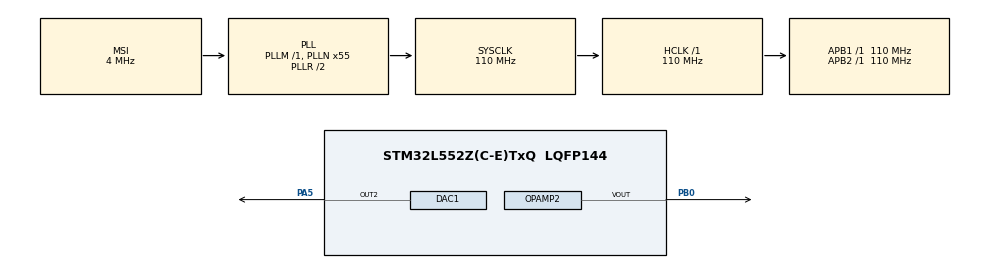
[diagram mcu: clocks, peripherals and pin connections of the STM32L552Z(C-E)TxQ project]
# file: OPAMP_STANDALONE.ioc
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DAC1.DAC_Channel-DAC_OUT2_ExtAndInt=DAC_CHANNEL_2
DAC1.DAC_Trigger-DAC_OUT2_ExtAndInt=DAC_TRIGGER_T2_TRGO
Dma.DAC1_CH2.0.Channel_PRIV_NPRIV=DMA_CHANNEL_NPRIV_DISABLE
Dma.DAC1_CH2.0.Direction=DMA_MEMORY_TO_PERIPH
Dma.DAC1_CH2.0.EventEnable=DISABLE
Dma.DAC1_CH2.0.Instance=DMA1_Channel1
Dma.DAC1_CH2.0.MemDataAlignment=DMA_MDATAALIGN_WORD
Dma.DAC1_CH2.0.MemInc=DMA_MINC_ENABLE
Dma.DAC1_CH2.0.Mode=DMA_CIRCULAR
Dma.DAC1_CH2.0.PeriphDataAlignment=DMA_PDATAALIGN_WORD
Dma.DAC1_CH2.0.PeriphInc=DMA_PINC_DISABLE
Dma.DAC1_CH2.0.Polarity=HAL_DMAMUX_REQ_GEN_RISING
Dma.DAC1_CH2.0.Priority=DMA_PRIORITY_HIGH
Dma.DAC1_CH2.0.RequestNumber=1
Dma.DAC1_CH2.0.SignalID=NONE
Dma.DAC1_CH2.0.SyncEnable=DISABLE
Dma.DAC1_CH2.0.SyncPolarity=HAL_DMAMUX_SYNC_NO_EVENT
Dma.DAC1_CH2.0.SyncRequestNumber=1
Dma.DAC1_CH2.0.SyncSignalID=NONE
Dma.Request0=DAC1_CH2
Mcu.Family=STM32L5
Mcu.Name=STM32L552Z(C-E)TxQ
Mcu.Package=LQFP144
NVIC.DAC_IRQn=true\:0\:0\:false\:false\:true\:true\:true\:true
NVIC.DMA1_Channel1_IRQn=true\:0\:0\:false\:false\:true\:false\:true\:true
NVIC.PriorityGroup=NVIC_PRIORITYGROUP_3
OPAMP2.PowerSupplyRange=OPAMP_POWERSUPPLY_HIGH
PA5.Signal=COMP_DAC12_group
PB0.Mode=Follower-DAC_OUT2-INP
PB0.Signal=OPAMP2_VOUT
ProjectManager.HeapSize=0x200
ProjectManager.StackSize=0x400
ProjectManager.TargetToolchain=EWARM V8.32
RCC.AHBFreq_Value=110000000
RCC.APB1Freq_Value=110000000
RCC.APB1TimFreq_Value=110000000
RCC.APB2Freq_Value=110000000
RCC.APB2TimFreq_Value=110000000
RCC.CortexFreq_Value=110000000
RCC.HCLKFreq_Value=110000000
RCC.HSE_VALUE=16000000
RCC.HSI48_VALUE=48000000
RCC.HSI_VALUE=16000000
RCC.LSE_VALUE=32768
RCC.MSI_VALUE=4000000
RCC.PLLN=55
RCC.SYSCLKFreq_VALUE=110000000
RCC.SYSCLKSource=RCC_SYSCLKSOURCE_PLLCLK
RCC.VCOOutputFreq_Value=220000000
SH.COMP_DAC12_group.0=DAC1_OUT2,DAC_OUT2_ExtAndInt
TIM2.Period=0xfff
TIM2.TIM_MasterOutputTrigger=TIM_TRGO_UPDATE
VP_ICACHE_VS_ICACHE.Mode=DirectMappedCache
VP_PWR_VS_DBSignals.Mode=DisableDeadBatterySignals
VP_TIM2_VS_ClockSourceINT.Mode=Internal
board=custom

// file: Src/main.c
/* USER CODE BEGIN Header */
/**
  ******************************************************************************
  * @file    OPAMP/OPAMP_STANDALONE/Src/main.c
  * @author  MCD Application Team
  * @brief   This example provides a short description of how to use the OPAMP
  *          peripheral to amplify several signals.
  ******************************************************************************
  * @attention
  *
  * Copyright (c) 2019 STMicroelectronics.
  * All rights reserved.
  *
  * This software is licensed under terms that can be found in the LICENSE file
  * in the root directory of this software component.
  * If no LICENSE file comes with this software, it is provided AS-IS.
  *
  ******************************************************************************
  */
/* USER CODE END Header */
#include "main.h"

/* USER CODE BEGIN PD */
const uint32_t Sine12bit[32] = {511, 611, 707, 796, 847, 874, 984, 1014, 1023,
                                1014, 984, 937, 874, 796, 707, 611, 511, 411,
                                315, 227, 149, 149, 38, 9, 0, 9, 38, 86, 149, 227,
                                315, 411};
/* USER CODE END PD */

DAC_HandleTypeDef hdac1;
DMA_HandleTypeDef hdma_dac1_ch2;

OPAMP_HandleTypeDef hopamp2;

TIM_HandleTypeDef htim2;

/* USER CODE BEGIN PV */
/* set to 1 after User push-button interrupt  */
__IO uint32_t UserButtonStatus = 0;
/* USER CODE END PV */

void SystemClock_Config(void);
static void MX_GPIO_Init(void);
static void MX_DMA_Init(void);
static void MX_ICACHE_Init(void);
static void MX_OPAMP2_Init(void);
static void MX_DAC1_Init(void);
static void MX_TIM2_Init(void);
/* USER CODE BEGIN PFP */
static void OPAMP_Config_Power(uint32_t powermode);
/* USER CODE END PFP */

/* USER CODE BEGIN 0 */
/**
  * @brief  Configure OPAMP.
  * @param  powermode: power mode in use
  * @retval None
  */
static void OPAMP_Config_Power(uint32_t powermode)
  {
    /* Deinit  OPAMP */
    HAL_OPAMP_DeInit(&hopamp2);

    /* Select power mode */
    if (powermode == OPAMP_POWERMODE_NORMAL)
    {
      MX_OPAMP2_Init();
    }
    else
    {
      hopamp2.Instance = OPAMP2;
      hopamp2.Init.PowerSupplyRange = OPAMP_POWERSUPPLY_HIGH;
      hopamp2.Init.Mode = OPAMP_FOLLOWER_MODE;
      hopamp2.Init.NonInvertingInput = OPAMP_NONINVERTINGINPUT_DAC_CH;
      hopamp2.Init.PowerMode = OPAMP_POWERMODE_LOWPOWER;
      hopamp2.Init.UserTrimming = OPAMP_TRIMMING_FACTORY;
      if (HAL_OPAMP_Init(&hopamp2) != HAL_OK)
      {
        Error_Handler();
      }
    }
}

/**
  * @brief  EXTI line rising detection callback.
  * @param  GPIO_Pin Specifies the port pin connected to corresponding EXTI line.
  * @retval None
  */

void HAL_GPIO_EXTI_Rising_Callback(uint16_t GPIO_Pin)
{
  static uint32_t first_transition_timing = 0;
  uint32_t current_transition_timing = 0;

  current_transition_timing = HAL_GetTick();

  /* 500 ms */
  if ((current_transition_timing - first_transition_timing) > 500)
  {
    /* Wait that user release the User push-button */
    while(BSP_PB_GetState(BUTTON_USER) == GPIO_PIN_SET)
    {
    }

    /* A genuine transition is detected */
    UserButtonStatus = 1;

    /* current transition timing becomes first transition timing */
    first_transition_timing = current_transition_timing;
  }
  else
  /* Next transitions within 500 ms window time span are ignored */
  {
  }
}
/* USER CODE END 0 */

int main(void)
{
  /* USER CODE BEGIN 1 */
  uint32_t examplestate = 0;
  /* USER CODE END 1 */

  /* MCU Configuration--------------------------------------------------------*/

  /* Reset of all peripherals, Initializes the Flash interface and the Systick. */
  HAL_Init();

  /* Configure the system clock */
  SystemClock_Config();

  /* Initialize all configured peripherals */
  MX_GPIO_Init();
  MX_DMA_Init();
  MX_ICACHE_Init();
  MX_OPAMP2_Init();
  MX_DAC1_Init();
  MX_TIM2_Init();
  /* USER CODE BEGIN 2 */

  /*##- Configure and enable the User push-button in EXTI mode used as DMA external request signal #####*/
  if (BSP_PB_Init(BUTTON_USER, BUTTON_MODE_EXTI) != BSP_ERROR_NONE)
  {
    while(1);
  }

  /* Enable TIM peripheral counter */
  HAL_TIM_Base_Start(&htim2);

  /* Start DAC with DMA used as input signal */
  if(HAL_DAC_Start_DMA(&hdac1, DAC_CHANNEL_2, (uint32_t*)Sine12bit,
                       sizeof (Sine12bit) / sizeof (uint32_t),
                       DAC_ALIGN_12B_R) != HAL_OK)
  {
    Error_Handler();
  }

  /* USER CODE END 2 */

  /* Infinite loop */
  /* USER CODE BEGIN WHILE */
  while (1)
  {

    /* Test if user an action occurred on the User push-button */
    if (UserButtonStatus == 1)
    {
      UserButtonStatus = 0;
      /* Change the mode */
      if (examplestate == 0)
      {
        /* normal mode */
        OPAMP_Config_Power(OPAMP_POWERMODE_NORMAL);
        examplestate= 1;
      }
      else /* normal mode */
      {
        /* Low power mode */
        OPAMP_Config_Power(OPAMP_POWERMODE_LOWPOWER);
        examplestate= 0;
      }

      if(HAL_OK != HAL_OPAMP_Start(&hopamp2))
      {
        Error_Handler();
      }
    }

    /* USER CODE END WHILE */

  }
}

void SystemClock_Config(void)
{
  RCC_OscInitTypeDef RCC_OscInitStruct = {0};
  RCC_ClkInitTypeDef RCC_ClkInitStruct = {0};

  /** Configure the main internal regulator output voltage
  */
  if (HAL_PWREx_ControlVoltageScaling(PWR_REGULATOR_VOLTAGE_SCALE0) != HAL_OK)
  {
    Error_Handler();
  }

  /** Initializes the RCC Oscillators according to the specified parameters
  * in the RCC_OscInitTypeDef structure.
  */
  RCC_OscInitStruct.OscillatorType = RCC_OSCILLATORTYPE_MSI;
  RCC_OscInitStruct.MSIState = RCC_MSI_ON;
  RCC_OscInitStruct.MSICalibrationValue = RCC_MSICALIBRATION_DEFAULT;
  RCC_OscInitStruct.MSIClockRange = RCC_MSIRANGE_6;
  RCC_OscInitStruct.PLL.PLLState = RCC_PLL_ON;
  RCC_OscInitStruct.PLL.PLLSource = RCC_PLLSOURCE_MSI;
  RCC_OscInitStruct.PLL.PLLM = 1;
  RCC_OscInitStruct.PLL.PLLN = 55;
  RCC_OscInitStruct.PLL.PLLP = RCC_PLLP_DIV7;
  RCC_OscInitStruct.PLL.PLLQ = RCC_PLLQ_DIV2;
  RCC_OscInitStruct.PLL.PLLR = RCC_PLLR_DIV2;
  if (HAL_RCC_OscConfig(&RCC_OscInitStruct) != HAL_OK)
  {
    Error_Handler();
  }

  /** Initializes the CPU, AHB and APB buses clocks
  */
  RCC_ClkInitStruct.ClockType = RCC_CLOCKTYPE_HCLK|RCC_CLOCKTYPE_SYSCLK
                              |RCC_CLOCKTYPE_PCLK1|RCC_CLOCKTYPE_PCLK2;
  RCC_ClkInitStruct.SYSCLKSource = RCC_SYSCLKSOURCE_PLLCLK;
  RCC_ClkInitStruct.AHBCLKDivider = RCC_SYSCLK_DIV1;
  RCC_ClkInitStruct.APB1CLKDivider = RCC_HCLK_DIV1;
  RCC_ClkInitStruct.APB2CLKDivider = RCC_HCLK_DIV1;

  if (HAL_RCC_ClockConfig(&RCC_ClkInitStruct, FLASH_LATENCY_5) != HAL_OK)
  {
    Error_Handler();
  }
}

static void MX_DAC1_Init(void)
{

  DAC_ChannelConfTypeDef sConfig = {0};

  /** DAC Initialization
  */
  hdac1.Instance = DAC1;
  if (HAL_DAC_Init(&hdac1) != HAL_OK)
  {
    Error_Handler();
  }

  /** DAC channel OUT2 config
  */
  sConfig.DAC_SampleAndHold = DAC_SAMPLEANDHOLD_DISABLE;
  sConfig.DAC_Trigger = DAC_TRIGGER_T2_TRGO;
  sConfig.DAC_HighFrequency = DAC_HIGH_FREQUENCY_INTERFACE_MODE_ABOVE_80MHZ;
  sConfig.DAC_OutputBuffer = DAC_OUTPUTBUFFER_ENABLE;
  sConfig.DAC_ConnectOnChipPeripheral = DAC_CHIPCONNECT_ENABLE;
  sConfig.DAC_UserTrimming = DAC_TRIMMING_FACTORY;
  if (HAL_DAC_ConfigChannel(&hdac1, &sConfig, DAC_CHANNEL_2) != HAL_OK)
  {
    Error_Handler();
  }

}

static void MX_ICACHE_Init(void)
{

  /** Enable instruction cache in 1-way (direct mapped cache)
  */
  if (HAL_ICACHE_ConfigAssociativityMode(ICACHE_1WAY) != HAL_OK)
  {
    Error_Handler();
  }
  if (HAL_ICACHE_Enable() != HAL_OK)
  {
    Error_Handler();
  }

}

static void MX_OPAMP2_Init(void)
{

  hopamp2.Instance = OPAMP2;
  hopamp2.Init.PowerSupplyRange = OPAMP_POWERSUPPLY_HIGH;
  hopamp2.Init.Mode = OPAMP_FOLLOWER_MODE;
  hopamp2.Init.NonInvertingInput = OPAMP_NONINVERTINGINPUT_DAC_CH;
  hopamp2.Init.PowerMode = OPAMP_POWERMODE_NORMALPOWER;
  hopamp2.Init.UserTrimming = OPAMP_TRIMMING_FACTORY;
  if (HAL_OPAMP_Init(&hopamp2) != HAL_OK)
  {
    Error_Handler();
  }

}

static void MX_TIM2_Init(void)
{

  TIM_ClockConfigTypeDef sClockSourceConfig = {0};
  TIM_MasterConfigTypeDef sMasterConfig = {0};

  htim2.Instance = TIM2;
  htim2.Init.Prescaler = 0;
  htim2.Init.CounterMode = TIM_COUNTERMODE_UP;
  htim2.Init.Period = 0xfff;
  htim2.Init.ClockDivision = TIM_CLOCKDIVISION_DIV1;
  htim2.Init.AutoReloadPreload = TIM_AUTORELOAD_PRELOAD_DISABLE;
  if (HAL_TIM_Base_Init(&htim2) != HAL_OK)
  {
    Error_Handler();
  }
  sClockSourceConfig.ClockSource = TIM_CLOCKSOURCE_INTERNAL;
  if (HAL_TIM_ConfigClockSource(&htim2, &sClockSourceConfig) != HAL_OK)
  {
    Error_Handler();
  }
  sMasterConfig.MasterOutputTrigger = TIM_TRGO_UPDATE;
  sMasterConfig.MasterSlaveMode = TIM_MASTERSLAVEMODE_DISABLE;
  if (HAL_TIMEx_MasterConfigSynchronization(&htim2, &sMasterConfig) != HAL_OK)
  {
    Error_Handler();
  }

}

static void MX_DMA_Init(void)
{

  /* DMA controller clock enable */
  __HAL_RCC_DMAMUX1_CLK_ENABLE();
  __HAL_RCC_DMA1_CLK_ENABLE();

  /* DMA interrupt init */
  /* DMA1_Channel1_IRQn interrupt configuration */
  HAL_NVIC_SetPriority(DMA1_Channel1_IRQn, 0, 0);
  HAL_NVIC_EnableIRQ(DMA1_Channel1_IRQn);

}

static void MX_GPIO_Init(void)
{

  /* GPIO Ports Clock Enable */
  __HAL_RCC_GPIOA_CLK_ENABLE();
  __HAL_RCC_GPIOB_CLK_ENABLE();

}

void Error_Handler(void)
{
  while(1)
  {
  }
}

#ifdef  USE_FULL_ASSERT
/**
  * @brief  Reports the name of the source file and the source line number
  *         where the assert_param error has occurred.
  * @param  file: pointer to the source file name
  * @param  line: assert_param error line source number
  * @retval None
  */
void assert_failed(uint8_t *file, uint32_t line)
{
  /* USER CODE BEGIN 6 */
  /* User can add his own implementation to report the file name and line number,
     ex: printf("Wrong parameters value: file %s on line %d\r\n", file, line) */
  /* Infinite loop */
  while (1)
  {}
  /* USER CODE END 6 */
}
#endif /* USE_FULL_ASSERT */
